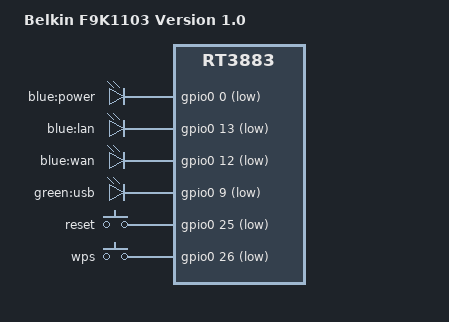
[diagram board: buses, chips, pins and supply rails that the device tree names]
// SPDX-License-Identifier: GPL-2.0-or-later OR MIT
/*
 * Belkin F9K1103 v1 (N750 DB)
 *
 * Port basis:
 * - OpenWrt 23.05.5 rt3883_belkin_f9k110x.dtsi
 * - F9K1103-specific GPIOs from Padavan BN750DB board.h
 *
 * PORT-WIP: not yet flash/runtime verified on physical F9K1103 v1.
 */

#include "rt3883_belkin_f9k110x.dtsi"

#include <dt-bindings/gpio/gpio.h>
#include <dt-bindings/input/input.h>

/ {
	compatible = "belkin,f9k1103v1", "ralink,rt3883-soc";
	model = "Belkin F9K1103 Version 1.0";

	aliases {
		led-boot = &led_power;
		led-failsafe = &led_power;
		led-running = &led_power;
		led-upgrade = &led_power;
	};

	leds {
		compatible = "gpio-leds";

		led_power: power {
			label = "blue:power";
			gpios = <&gpio0 0 GPIO_ACTIVE_LOW>;
		};

		lan {
			label = "blue:lan";
			gpios = <&gpio0 13 GPIO_ACTIVE_LOW>;
		};

		wan {
			label = "blue:wan";
			gpios = <&gpio0 12 GPIO_ACTIVE_LOW>;
		};

		usb {
			label = "green:usb";
			gpios = <&gpio0 9 GPIO_ACTIVE_LOW>;
		};
	};

	keys {
		compatible = "gpio-keys-polled";
		poll-interval = <100>;

		reset {
			label = "reset";
			gpios = <&gpio0 25 GPIO_ACTIVE_LOW>;
			linux,code = <KEY_RESTART>;
		};

		wps {
			label = "wps";
			gpios = <&gpio0 26 GPIO_ACTIVE_LOW>;
			linux,code = <KEY_WPS_BUTTON>;
		};
	};
};
